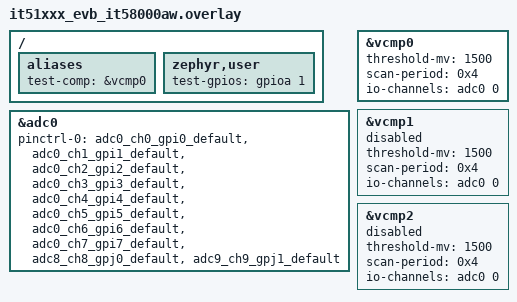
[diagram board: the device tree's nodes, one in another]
/*
 * Copyright (c) 2026 ITE Technology Corporation
 *
 * SPDX-License-Identifier: Apache-2.0
 */

#include <zephyr/dt-bindings/gpio/gpio.h>

/ {
	aliases {
		test-comp = &vcmp0;
	};

	zephyr,user {
		test-gpios = <&gpioa 1 GPIO_ACTIVE_HIGH>;
	};
};

&adc0 {
	status = "okay";
	pinctrl-0 = <&adc0_ch0_gpi0_default &adc0_ch1_gpi1_default
		     &adc0_ch2_gpi2_default &adc0_ch3_gpi3_default
		     &adc0_ch4_gpi4_default &adc0_ch5_gpi5_default
		     &adc0_ch6_gpi6_default &adc0_ch7_gpi7_default
		     &adc8_ch8_gpj0_default &adc9_ch9_gpj1_default>;
	pinctrl-names = "default";
};

&vcmp0 {
	status = "okay";
	threshold-mv = <1500>;
	scan-period = <0x4>;
	io-channels = <&adc0 0>;
};

&vcmp1 {
	status = "disabled";
	threshold-mv = <1500>;
	scan-period = <0x4>;
	io-channels = <&adc0 0>;
};

&vcmp2 {
	status = "disabled";
	threshold-mv = <1500>;
	scan-period = <0x4>;
	io-channels = <&adc0 0>;
};
